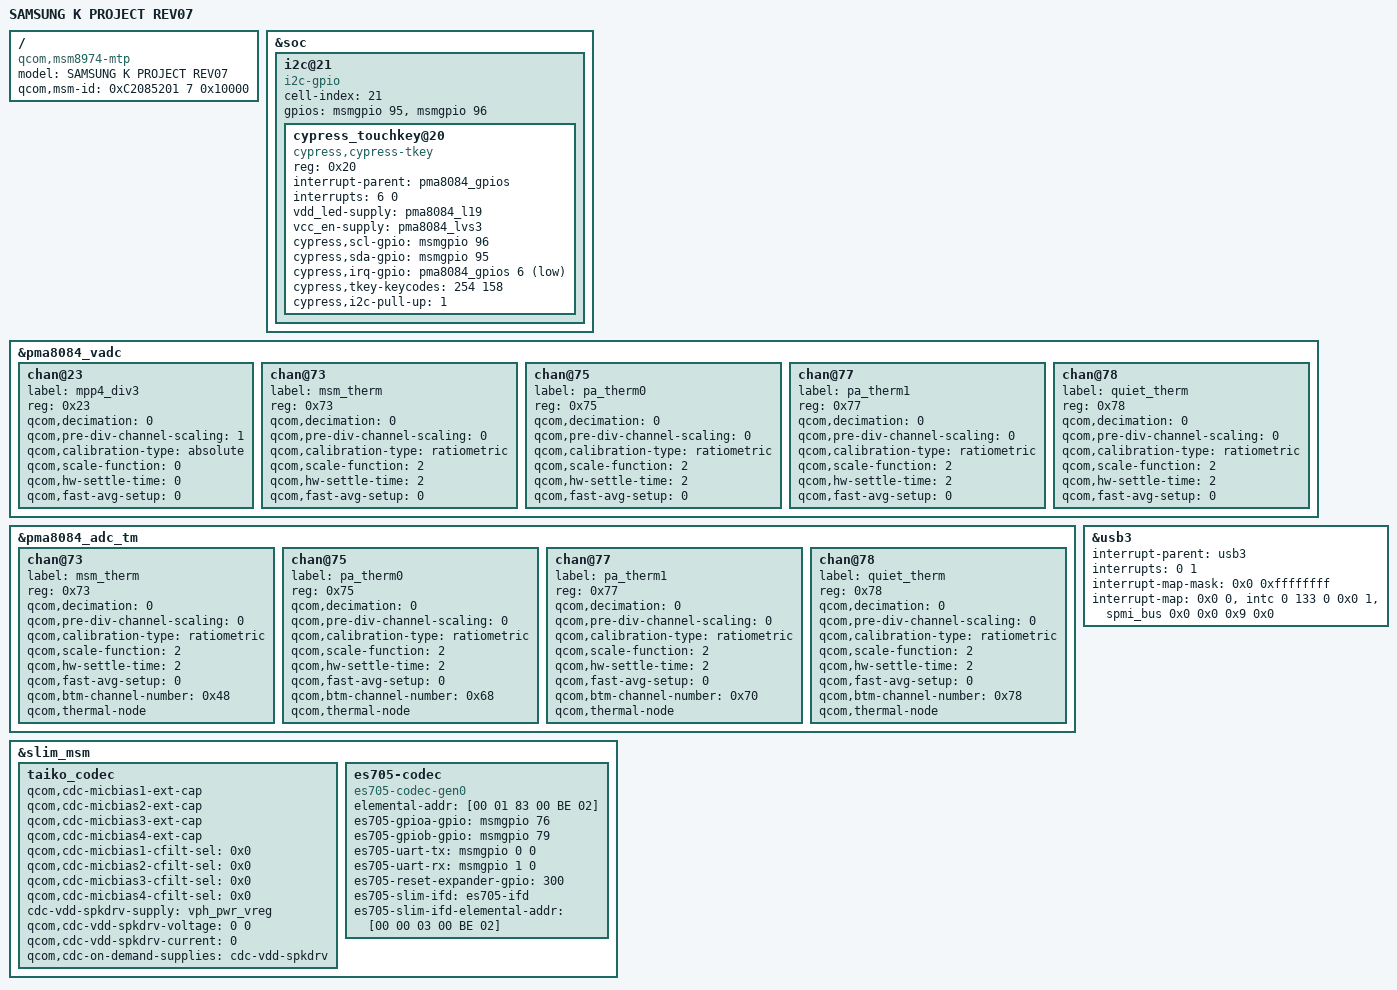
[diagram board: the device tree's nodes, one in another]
/* Copyright (c) 2013, The Linux Foundation. All rights reserved.
 *
 * This program is free software; you can redistribute it and/or modify
 * it under the terms of the GNU General Public License version 2 and
 * only version 2 as published by the Free Software Foundation.
 *
 * This program is distributed in the hope that it will be useful,
 * but WITHOUT ANY WARRANTY; without even the implied warranty of
 * MERCHANTABILITY or FITNESS FOR A PARTICULAR PURPOSE.  See the
 * GNU General Public License for more details.
 */

/dts-v1/;

/include/ "msm8974pro-sec.dtsi"
/include/ "msm8974pro-max77804k-k.dtsi"
/include/ "msm8974pro-ac-sec-k-r07.dtsi"
/include/ "msm8974pro-tdmb-klte-r00.dtsi"

/ {
	model = "SAMSUNG K PROJECT REV07";
	compatible = "qcom,msm8974-mtp", "qcom,msm8974", "qcom,mtp";
	/*QCOM BOARD REV TYPE...*/
	/*qcom,msm-id = <194 8 0x10000>;*/
	/*SEC BOARD REV TYPE...*/
        qcom,msm-id = <0xC2085201 7 0x10000>;
        /* [31:24] chip-id, [23:16] platform-id, [15:8] national code, [7:0] operator revision, reserved */
};

&soc {
	i2c@21 {
		cell-index = <21>;
		compatible = "i2c-gpio";
		gpios = <&msmgpio 95 0 /* sda */
			 &msmgpio 96 0 /* scl */
			>;
		#address-cells = <1>;
		#size-cells = <0>;

		cypress_touchkey@20 {
			compatible = "cypress,cypress-tkey";
			reg = <0x20>;
			interrupt-parent = <&pma8084_gpios>;
			interrupts = <6 0>;
			vdd_led-supply = <&pma8084_l19>;
			vcc_en-supply = <&pma8084_lvs3>;
			cypress,scl-gpio = <&msmgpio 96 0x00>;
			cypress,sda-gpio = <&msmgpio 95 0x00>;
			cypress,irq-gpio = <&pma8084_gpios 6 0x1>;
			cypress,tkey-keycodes = <254 158>;
			cypress,i2c-pull-up = <1>;
		};
	};
};

&pma8084_vadc {
	chan@23 {
		label = "mpp4_div3";
		reg = <0x23>;
		qcom,decimation = <0>;
		qcom,pre-div-channel-scaling = <1>; /* 1:3 scaling */
		qcom,calibration-type = "absolute";
		qcom,scale-function = <0>;
		qcom,hw-settle-time = <0>;
		qcom,fast-avg-setup = <0>;
	};
	
	chan@73 {
		label = "msm_therm";
		reg = <0x73>;
		qcom,decimation = <0>;
		qcom,pre-div-channel-scaling = <0>;
		qcom,calibration-type = "ratiometric";
		qcom,scale-function = <2>;
		qcom,hw-settle-time = <2>;
		qcom,fast-avg-setup = <0>;
	};

	chan@75 {
		label = "pa_therm0";
		reg = <0x75>;
		qcom,decimation = <0>;
		qcom,pre-div-channel-scaling = <0>;
		qcom,calibration-type = "ratiometric";
		qcom,scale-function = <2>;
		qcom,hw-settle-time = <2>;
		qcom,fast-avg-setup = <0>;
	};

	chan@77 {
		label = "pa_therm1";
		reg = <0x77>;
		qcom,decimation = <0>;
		qcom,pre-div-channel-scaling = <0>;
		qcom,calibration-type = "ratiometric";
		qcom,scale-function = <2>;
		qcom,hw-settle-time = <2>;
		qcom,fast-avg-setup = <0>;
	};

	chan@78 {
		label = "quiet_therm";
		reg = <0x78>;
		qcom,decimation = <0>;
		qcom,pre-div-channel-scaling = <0>;
		qcom,calibration-type = "ratiometric";
		qcom,scale-function = <2>;
		qcom,hw-settle-time = <2>;
		qcom,fast-avg-setup = <0>;
	};
};

&pma8084_adc_tm {
	chan@73 {
		label = "msm_therm";
		reg = <0x73>;
		qcom,decimation = <0>;
		qcom,pre-div-channel-scaling = <0>;
		qcom,calibration-type = "ratiometric";
		qcom,scale-function = <2>;
		qcom,hw-settle-time = <2>;
		qcom,fast-avg-setup = <0>;
		qcom,btm-channel-number = <0x48>;
		qcom,thermal-node;
	};

	chan@75 {
		label = "pa_therm0";
		reg = <0x75>;
		qcom,decimation = <0>;
		qcom,pre-div-channel-scaling = <0>;
		qcom,calibration-type = "ratiometric";
		qcom,scale-function = <2>;
		qcom,hw-settle-time = <2>;
		qcom,fast-avg-setup = <0>;
		qcom,btm-channel-number = <0x68>;
		qcom,thermal-node;
	};

	chan@77 {
		label = "pa_therm1";
		reg = <0x77>;
		qcom,decimation = <0>;
		qcom,pre-div-channel-scaling = <0>;
		qcom,calibration-type = "ratiometric";
		qcom,scale-function = <2>;
		qcom,hw-settle-time = <2>;
		qcom,fast-avg-setup = <0>;
		qcom,btm-channel-number = <0x70>;
		qcom,thermal-node;
	};

	chan@78 {
		label = "quiet_therm";
		reg = <0x78>;
		qcom,decimation = <0>;
		qcom,pre-div-channel-scaling = <0>;
		qcom,calibration-type = "ratiometric";
		qcom,scale-function = <2>;
		qcom,hw-settle-time = <2>;
		qcom,fast-avg-setup = <0>;
		qcom,btm-channel-number = <0x78>;
		qcom,thermal-node;
	};
};

&usb3 {
	interrupt-names = "irq", "otg_irq", "hs_phy_irq", "pmic_id_irq";
	interrupt-parent = <&usb3>;
	interrupts = <0 1>;
	#interrupt-cells = <1>;
	interrupt-map-mask = <0x0 0xffffffff>;
	interrupt-map = <0x0 0 &intc 0 133 0
			 0x0 1 &spmi_bus 0x0 0x0 0x9 0x0>;
	interrupt-names = "hs_phy_irq", "pmic_id_irq";
	/*qcom,misc-ref = <&pm8941_misc>;*/
};

&slim_msm {
	taiko_codec {
		qcom,cdc-micbias1-ext-cap;
		qcom,cdc-micbias2-ext-cap;
		qcom,cdc-micbias3-ext-cap;
		qcom,cdc-micbias4-ext-cap;

		qcom,cdc-micbias1-cfilt-sel = <0x0>;
		qcom,cdc-micbias2-cfilt-sel = <0x0>;
		qcom,cdc-micbias3-cfilt-sel = <0x0>;
		qcom,cdc-micbias4-cfilt-sel = <0x0>;

		/*
		 * Liquid has external spkrdrv supply. Give a dummy supply to
		 * make codec driver's happy.
		 */
		cdc-vdd-spkdrv-supply = <&vph_pwr_vreg>;
		qcom,cdc-vdd-spkdrv-voltage = <0 0>;
		qcom,cdc-vdd-spkdrv-current = <0>;

		qcom,cdc-on-demand-supplies = "cdc-vdd-spkdrv";
	};
	es705-codec {
		compatible = "es705-codec-gen0";
		elemental-addr = [00 01 83 00 BE 02];

		es705-gpioa-gpio = <&msmgpio 76 0>;
		es705-gpiob-gpio = <&msmgpio 79 0>;
		es705-uart-tx = <&msmgpio 0 0>;
		es705-uart-rx = <&msmgpio 1 0>;
		es705-reset-expander-gpio = <300>;

		es705-slim-ifd = "es705-ifd";
		es705-slim-ifd-elemental-addr = [00 00 03 00 BE 02];
	};
};
